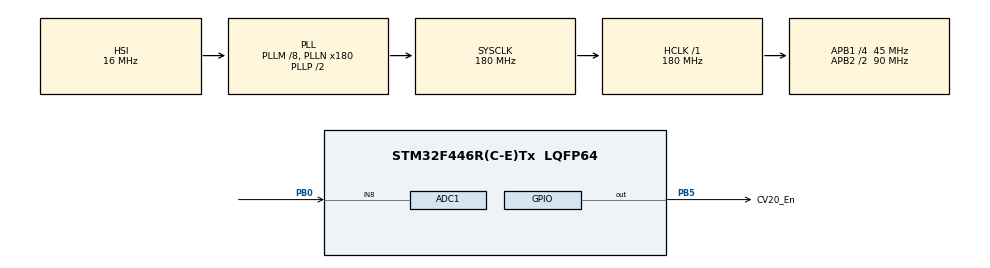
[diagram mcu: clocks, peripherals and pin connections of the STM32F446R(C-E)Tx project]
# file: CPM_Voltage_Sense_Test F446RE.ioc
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ADC1.Channel-1\#ChannelRegularConversion=ADC_CHANNEL_8
ADC1.NbrOfConversionFlag=1
ADC1.Rank-1\#ChannelRegularConversion=1
ADC1.SamplingTime-1\#ChannelRegularConversion=ADC_SAMPLETIME_3CYCLES
ADC1.master=1
Mcu.Family=STM32F4
Mcu.Name=STM32F446R(C-E)Tx
Mcu.Package=LQFP64
NVIC.PriorityGroup=NVIC_PRIORITYGROUP_4
NVIC.RCC_IRQn=true\:0\:0\:false\:false\:true\:true\:false\:true
PB0.Signal=ADCx_IN8
PB5.GPIO_Label=CV20_En
PB5.GPIO_PuPd=GPIO_PULLDOWN
PB5.Signal=GPIO_Output
PC14-OSC32_IN.Mode=LSE-External-Oscillator
PC14-OSC32_IN.Signal=RCC_OSC32_IN
PC15-OSC32_OUT.Mode=LSE-External-Oscillator
PC15-OSC32_OUT.Signal=RCC_OSC32_OUT
PH0-OSC_IN.Mode=HSE-External-Oscillator
PH0-OSC_IN.Signal=RCC_OSC_IN
PH1-OSC_OUT.Mode=HSE-External-Oscillator
PH1-OSC_OUT.Signal=RCC_OSC_OUT
ProjectManager.HeapSize=0x200
ProjectManager.StackSize=0x400
ProjectManager.TargetToolchain=STM32CubeIDE
RCC.AHBFreq_Value=180000000
RCC.APB1CLKDivider=RCC_HCLK_DIV4
RCC.APB1Freq_Value=45000000
RCC.APB1TimFreq_Value=90000000
RCC.APB2CLKDivider=RCC_HCLK_DIV2
RCC.APB2Freq_Value=90000000
RCC.APB2TimFreq_Value=180000000
RCC.CortexFreq_Value=180000000
RCC.HCLKFreq_Value=180000000
RCC.PLLM=8
RCC.PLLN=180
RCC.SYSCLKFreq_VALUE=180000000
RCC.SYSCLKSource=RCC_SYSCLKSOURCE_PLLCLK
RCC.USBFreq_Value=180000000
RCC.VCOOutputFreq_Value=360000000
SH.ADCx_IN8.0=ADC1_IN8,IN8
board=custom

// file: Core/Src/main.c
/* USER CODE BEGIN Header */
/**
  ******************************************************************************
  * @file           : main.c
  * @brief          : Main program body
  ******************************************************************************
  * @attention
  *
  * Copyright (c) 2023 STMicroelectronics.
  * All rights reserved.
  *
  * This software is licensed under terms that can be found in the LICENSE file
  * in the root directory of this software component.
  * If no LICENSE file comes with this software, it is provided AS-IS.
  *
  ******************************************************************************
  */
/* USER CODE END Header */
#include "main.h"

/* USER CODE BEGIN Includes */
#include <stdbool.h>
/* USER CODE END Includes */

/* USER CODE BEGIN PD */
#define CV_En_Pin GPIO_PIN_6
/* USER CODE END PD */

ADC_HandleTypeDef hadc1;
DMA_HandleTypeDef hdma_adc1;

void SystemClock_Config(void);
static void MX_GPIO_Init(void);
static void MX_DMA_Init(void);
static void MX_ADC1_Init(void);

/* USER CODE BEGIN 0 */
	float CpmVoltage = 5.6;
	bool CV_Voltage_ui=0;
/* USER CODE END 0 */

int main(void)
{

  /* MCU Configuration--------------------------------------------------------*/

  /* Reset of all peripherals, Initializes the Flash interface and the Systick. */
  HAL_Init();

  /* Configure the system clock */
  SystemClock_Config();

  /* Initialize all configured peripherals */
  MX_GPIO_Init();
  MX_DMA_Init();
  MX_ADC1_Init();
  /* USER CODE BEGIN 2 */
  HAL_ADC_Init(&hadc1);

  /* USER CODE END 2 */

  /* Infinite loop */
  /* USER CODE BEGIN WHILE */
  while (1)
  {
	  HAL_GPIO_WritePin(GPIOA, CV_En_Pin, CV_Voltage_ui);
	  HAL_ADC_Start(&hadc1);
	  CpmVoltage = HAL_ADC_GetValue(&hadc1)*(5.0/4096.0);
	  HAL_Delay(100);
	  HAL_ADC_Stop(&hadc1);
	  HAL_Delay(100);

    /* USER CODE END WHILE */

  }
}

void SystemClock_Config(void)
{
  RCC_OscInitTypeDef RCC_OscInitStruct = {0};
  RCC_ClkInitTypeDef RCC_ClkInitStruct = {0};

  /** Configure the main internal regulator output voltage
  */
  __HAL_RCC_PWR_CLK_ENABLE();
  __HAL_PWR_VOLTAGESCALING_CONFIG(PWR_REGULATOR_VOLTAGE_SCALE1);

  /** Initializes the RCC Oscillators according to the specified parameters
  * in the RCC_OscInitTypeDef structure.
  */
  RCC_OscInitStruct.OscillatorType = RCC_OSCILLATORTYPE_HSI;
  RCC_OscInitStruct.HSIState = RCC_HSI_ON;
  RCC_OscInitStruct.HSICalibrationValue = RCC_HSICALIBRATION_DEFAULT;
  RCC_OscInitStruct.PLL.PLLState = RCC_PLL_ON;
  RCC_OscInitStruct.PLL.PLLSource = RCC_PLLSOURCE_HSI;
  RCC_OscInitStruct.PLL.PLLM = 8;
  RCC_OscInitStruct.PLL.PLLN = 180;
  RCC_OscInitStruct.PLL.PLLP = RCC_PLLP_DIV2;
  RCC_OscInitStruct.PLL.PLLQ = 2;
  RCC_OscInitStruct.PLL.PLLR = 2;
  if (HAL_RCC_OscConfig(&RCC_OscInitStruct) != HAL_OK)
  {
    Error_Handler();
  }

  /** Activate the Over-Drive mode
  */
  if (HAL_PWREx_EnableOverDrive() != HAL_OK)
  {
    Error_Handler();
  }

  /** Initializes the CPU, AHB and APB buses clocks
  */
  RCC_ClkInitStruct.ClockType = RCC_CLOCKTYPE_HCLK|RCC_CLOCKTYPE_SYSCLK
                              |RCC_CLOCKTYPE_PCLK1|RCC_CLOCKTYPE_PCLK2;
  RCC_ClkInitStruct.SYSCLKSource = RCC_SYSCLKSOURCE_PLLCLK;
  RCC_ClkInitStruct.AHBCLKDivider = RCC_SYSCLK_DIV1;
  RCC_ClkInitStruct.APB1CLKDivider = RCC_HCLK_DIV4;
  RCC_ClkInitStruct.APB2CLKDivider = RCC_HCLK_DIV2;

  if (HAL_RCC_ClockConfig(&RCC_ClkInitStruct, FLASH_LATENCY_5) != HAL_OK)
  {
    Error_Handler();
  }
}

static void MX_ADC1_Init(void)
{

  ADC_ChannelConfTypeDef sConfig = {0};

  /** Configure the global features of the ADC (Clock, Resolution, Data Alignment and number of conversion)
  */
  hadc1.Instance = ADC1;
  hadc1.Init.ClockPrescaler = ADC_CLOCK_SYNC_PCLK_DIV8;
  hadc1.Init.Resolution = ADC_RESOLUTION_12B;
  hadc1.Init.ScanConvMode = DISABLE;
  hadc1.Init.ContinuousConvMode = ENABLE;
  hadc1.Init.DiscontinuousConvMode = DISABLE;
  hadc1.Init.ExternalTrigConvEdge = ADC_EXTERNALTRIGCONVEDGE_NONE;
  hadc1.Init.ExternalTrigConv = ADC_SOFTWARE_START;
  hadc1.Init.DataAlign = ADC_DATAALIGN_RIGHT;
  hadc1.Init.NbrOfConversion = 1;
  hadc1.Init.DMAContinuousRequests = ENABLE;
  hadc1.Init.EOCSelection = ADC_EOC_SINGLE_CONV;
  if (HAL_ADC_Init(&hadc1) != HAL_OK)
  {
    Error_Handler();
  }

  /** Configure for the selected ADC regular channel its corresponding rank in the sequencer and its sample time.
  */
  sConfig.Channel = ADC_CHANNEL_0;
  sConfig.Rank = 1;
  sConfig.SamplingTime = ADC_SAMPLETIME_3CYCLES;
  if (HAL_ADC_ConfigChannel(&hadc1, &sConfig) != HAL_OK)
  {
    Error_Handler();
  }

}

static void MX_DMA_Init(void)
{

  /* DMA controller clock enable */
  __HAL_RCC_DMA2_CLK_ENABLE();

  /* DMA interrupt init */
  /* DMA2_Stream0_IRQn interrupt configuration */
  HAL_NVIC_SetPriority(DMA2_Stream0_IRQn, 0, 0);
  HAL_NVIC_EnableIRQ(DMA2_Stream0_IRQn);

}

static void MX_GPIO_Init(void)
{
  GPIO_InitTypeDef GPIO_InitStruct = {0};

  /* GPIO Ports Clock Enable */
  __HAL_RCC_GPIOC_CLK_ENABLE();
  __HAL_RCC_GPIOH_CLK_ENABLE();
  __HAL_RCC_GPIOA_CLK_ENABLE();

  /*Configure GPIO pin Output Level */
  HAL_GPIO_WritePin(CV_Enable_GPIO_Port, CV_Enable_Pin, GPIO_PIN_RESET);

  /*Configure GPIO pin : CV_Enable_Pin */
  GPIO_InitStruct.Pin = CV_Enable_Pin;
  GPIO_InitStruct.Mode = GPIO_MODE_OUTPUT_PP;
  GPIO_InitStruct.Pull = GPIO_PULLDOWN;
  GPIO_InitStruct.Speed = GPIO_SPEED_FREQ_LOW;
  HAL_GPIO_Init(CV_Enable_GPIO_Port, &GPIO_InitStruct);

}

/* USER CODE BEGIN 4 */
int _write(int file, char *ptr, int len)
{
	int DataIdx;

	for (DataIdx = 0; DataIdx < len; DataIdx++)
	{
		ITM_SendChar(*ptr++);
	}
	return len;
}
/* USER CODE END 4 */

void Error_Handler(void)
{
  __disable_irq();
  while (1)
  {
  }
}
